# MK61F15WS register map
File version: 1.6
Registers are 32-bit, read-write, reset 0x0 unless marked. A register's access mark holds for its fields unless they carry their own. Offsets are from the block's base; [hi:lo] are bit positions; {n}, {i} and the like mark numbered series; 'fields as' and 'values as' point back to an identical list.

## AXBS — Crossbar switch
Base 0x40004000; register names take the prefix AXBS_
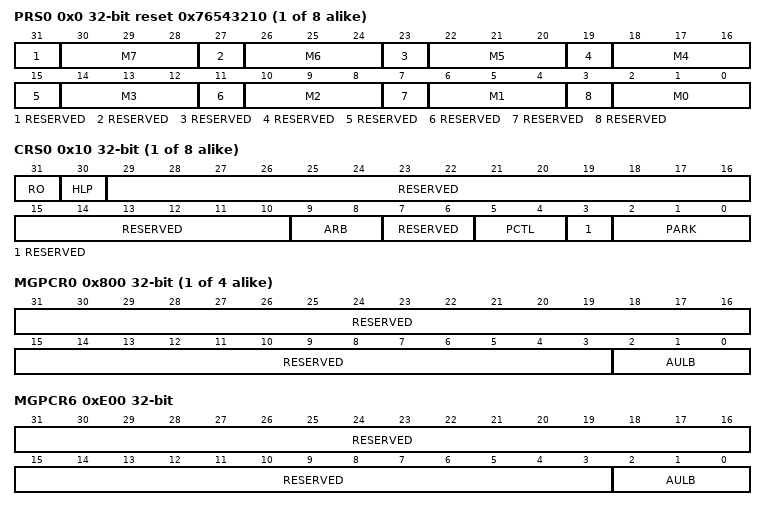
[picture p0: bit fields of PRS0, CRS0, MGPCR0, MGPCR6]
{0x0+0x100*i} PRS{i} (i=0..7) reset 0x76543210 — Priority Registers Slave
  [31] RESERVED ro
  [4n+2:4n] M{n} (n=0..7) — Master {n} Priority. Sets the arbitration priority for this port on the associated slave port.
    0=This master has level 1, or highest, priority when accessing the slave port; {v}=This master has level {v+1} priority when accessing the slave port (v=1..6); 7=This master has level 8, or lowest, priority when accessing the slave port
  [27] RESERVED ro
  [23] RESERVED ro
  [19] RESERVED ro
  [15] RESERVED ro
  [11] RESERVED ro
  [7] RESERVED ro
  [3] RESERVED ro
{0x10+0x100*i} CRS{i} (i=0..7) — Control Register
  [31] RO — Read Only
    0=The slave port's registers are writeable; 1=The slave port's registers are read-only and cannot be written. Attempted writes have no effect on the registers and result in a bus error response.
  [30] HLP — Halt Low Priority
    0=The low power mode request has the highest priority for arbitration on this slave port; 1=The low power mode request has the lowest initial priority for arbitration on this slave port
  [29:10] RESERVED ro
  [9:8] ARB — Arbitration Mode
    0=Fixed priority; 1=Round-robin, or rotating, priority
  [7:6] RESERVED ro
  [5:4] PCTL — Parking Control
    0=When no master makes a request, the arbiter parks the slave port on the master port defined by the PARK field; 1=When no master makes a request, the arbiter parks the slave port on the last master to be in control of the slave port; 2=When no master makes a request, the slave port is not parked on a master and the arbiter drives all outputs to a constant safe state
  [3] RESERVED ro
  [2:0] PARK
    {v}=Park on master port M{v} (v=0..7)
{0x800+0x100*i} MGPCR{i} (i=0..3) — Master General Purpose Control Register
  [31:3] RESERVED ro
  [2:0] AULB — Arbitrates On Undefined Length Bursts
    0=No arbitration is allowed during an undefined length burst; 1=Arbitration is allowed at any time during an undefined length burst; 2=Arbitration is allowed after four beats of an undefined length burst; 3=Arbitration is allowed after eight beats of an undefined length burst; 4=Arbitration is allowed after 16 beats of an undefined length burst
0xE00 MGPCR6 — Master General Purpose Control Register
  fields as MGPCR0
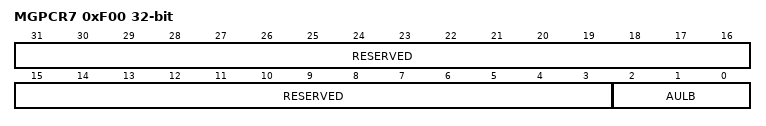
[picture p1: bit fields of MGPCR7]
0xF00 MGPCR7 — Master General Purpose Control Register
  fields as MGPCR0

## DMAMUX0 — DMA channel multiplexor
Base 0x40021000; register names take the prefix DMAMUX0_
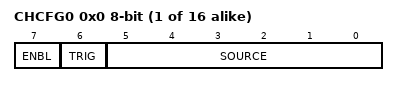
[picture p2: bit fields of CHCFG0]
{0x0+i} CHCFG{i} (i=0..15) 8-bit — Channel Configuration Register
  [7] ENBL — DMA Channel Enable
    0=DMA channel is disabled. This mode is primarily used during configuration of the DMA Mux. The DMA has separate channel enables/disables, which should be used to disable or re-configure a DMA channel.; 1=DMA channel is enabled
  [6] TRIG — DMA Channel Trigger Enable
    0=Triggering is disabled. If triggering is disabled, and the ENBL bit is set, the DMA Channel will simply route the specified source to the DMA channel. (normal mode); 1=Triggering is enabled. If triggering is enabled, and the ENBL bit is set, the DMAMUX is in periodic trigger mode.
  [5:0] SOURCE — DMA Channel Source (slot)

## DMAMUX1 — DMA channel multiplexor
Base 0x40022000; register names take the prefix DMAMUX1_
Registers as DMAMUX0.

## CRC — Cyclic Redundancy Check
Base 0x40032000; register names take the prefix CRC_
0x00 CRCLL 8-bit reset 0xFF (CRC view) — CRC_CRCLL register.
  [7:0] CRCLL — CRCLL stores the first 8 bits of the 32 bit CRC
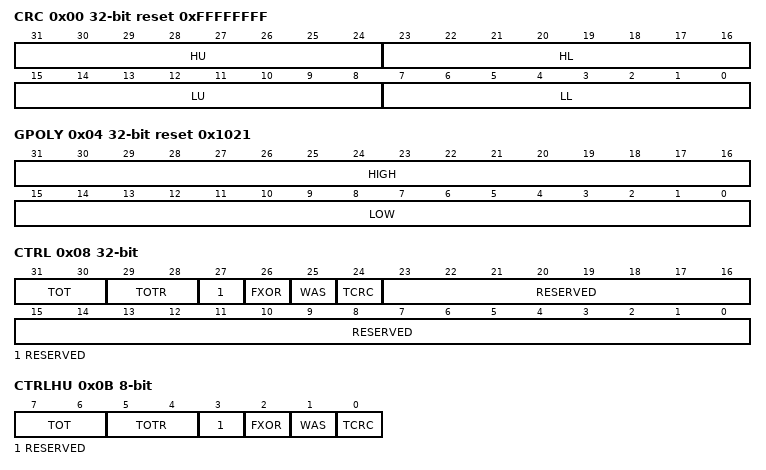
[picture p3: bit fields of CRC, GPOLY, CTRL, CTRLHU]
0x00 CRC reset 0xFFFFFFFF (CRC view) — CRC Data Register
  [31:24] HU — CRC High Upper Byte
  [23:16] HL — CRC High Lower Byte
  [15:8] LU — CRC Low Upper Byte
  [7:0] LL — CRC Low Lower Byte
0x00 CRCL 16-bit reset 0xFFFF (CRC view) — CRC_CRCL register.
  [15:0] CRCL — CRCL stores the lower 16 bits of the 16/32 bit CRC
0x01 CRCLU 8-bit reset 0xFF — CRC_CRCLU register.
  [7:0] CRCLU — CRCLL stores the second 8 bits of the 32 bit CRC
0x02 CRCHL 8-bit reset 0xFF (CRC view) — CRC_CRCHL register.
  [7:0] CRCHL — CRCHL stores the third 8 bits of the 32 bit CRC
0x02 CRCH 16-bit reset 0xFFFF (CRC view) — CRC_CRCH register.
  [15:0] CRCH — CRCH stores the high 16 bits of the 16/32 bit CRC
0x03 CRCHU 8-bit reset 0xFF — CRC_CRCHU register.
  [7:0] CRCHU — CRCHU stores the fourth 8 bits of the 32 bit CRC
0x04 GPOLY reset 0x1021 (CRC view) — CRC Polynomial Register
  [31:16] HIGH — High polynominal half-word
  [15:0] LOW — Low polynominal half-word
0x04 GPOLYLL 8-bit reset 0xFF (CRC view) — CRC_GPOLYLL register.
  [7:0] GPOLYLL — POLYLL stores the first 8 bits of the 32 bit CRC
0x04 GPOLYL 16-bit reset 0xFFFF (CRC view) — CRC_GPOLYL register.
  [15:0] GPOLYL — POLYL stores the lower 16 bits of the 16/32 bit CRC polynomial value
0x05 GPOLYLU 8-bit reset 0xFF — CRC_GPOLYLU register.
  [7:0] GPOLYLU — POLYLL stores the second 8 bits of the 32 bit CRC
0x06 GPOLYH 16-bit reset 0xFFFF (CRC view) — CRC_GPOLYH register.
  [15:0] GPOLYH — POLYH stores the high 16 bits of the 16/32 bit CRC polynomial value
0x06 GPOLYHL 8-bit reset 0xFF (CRC view) — CRC_GPOLYHL register.
  [7:0] GPOLYHL — POLYHL stores the third 8 bits of the 32 bit CRC
0x07 GPOLYHU 8-bit reset 0xFF — CRC_GPOLYHU register.
  [7:0] GPOLYHU — POLYHU stores the fourth 8 bits of the 32 bit CRC
0x08 CTRL — CRC Control Register
  [31:30] TOT — Type of Transpose for Writes
    0=No transposition; 1=Bits in bytes are transposed; bytes are not transposed; 2=Both bits in bytes and bytes are transposed; 3=Only bytes are transposed; no bits in a byte are transposed
  [29:28] TOTR — Type of Transpose for Read
    values as TOT
  [27] RESERVED ro
  [26] FXOR — Complement Read of CRC data register
    0=No XOR on reading; 1=Invert or complement the read value of the CRC data register
  [25] WAS — Write CRC data register as seed
    0=Writes to the CRC data register are data values; 1=Writes to the CRC data register are seed values
  [24] TCRC
    0=16-bit CRC protocol; 1=32-bit CRC protocol
  [23:0] RESERVED ro
0x0B CTRLHU 8-bit — CRC_CTRLHU register.
  [7:6] TOT
    0=No Transposition; 1=Bits in bytes are transposed, bytes are not transposed; 2=Both bits in bytes and bytes are transposed; 3=Only bytes are transposed; no bits in a byte are transposed
  [5:4] TOTR
    values as TOT
  [3] RESERVED ro
  [2] FXOR
    0=No XOR on reading; 1=Invert or complement the read value of CRC data register
  [1] WAS
    0=Writes to CRC data register are data values; 1=Writes to CRC data reguster are seed values
  [0] TCRC
    0=16-bit CRC protocol; 1=32-bit CRC protocol
